# YTM32Z1LS0 register map
Vendor: YTMicro; File version: 1.2
CPU: CM0PLUS r0p1, little endian, MPU, FPU, 2 interrupt priority bits
Registers are 32-bit, read-write, reset 0x0 unless marked. A register's access mark holds for its fields unless they carry their own. Offsets are from the block's base; [hi:lo] are bit positions; {n}, {i} and the like mark numbered series.

## pTMR0 — Periodic timer
Base 0x40037000; register names take the prefix pTMR0_
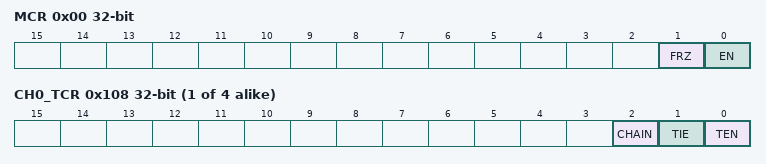
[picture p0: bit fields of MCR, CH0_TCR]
0x00 MCR
  [1] FRZ — Allows the timers to be stopped when the device enters debug mode.
    0=pTMR continues to run in debug mode; 1=pTMR stops in debug mode
  [0] EN — Enable pTMR module
    0=pTMR is disabled; 1=pTMR is enabled
{0x100+0x10*i} CH{i}_TSV (i=0..3) — Timer Start Value Register
  [31:0] STVAL — This register set the timer start value. The timer will count down until it reaches 0, then it will generate an interrupt and loads the value again. Writing a new value to this register will not restart the timer, instead the value will be loaded once the timer expires. To abort the current cycle and start a timer period with the new value, the timer must be disabled and enabled again.
{0x104+0x10*i} CH{i}_TCV (i=0..3) — Timer Current Value Register
  [31:0] CVAL — This register stands for current timer value when user read this register. The value of this register will be frozen in debug mode if MCR[FRZ] is set.
{0x108+0x10*i} CH{i}_TCR (i=0..3) — Timer Control Register
  [2] CHAIN — When setting this bit, it will link multi-channel in sequence to combine a new bits counter, it just links the front channel.
    0=Chaining is disabled, channel timer runs independently; 1=Chaining is enabled
  [1] TIE — Enable interrupt when setting this bit
    0=Disable timer interrupt of corresponding channel; 1=Enable timer interrupt of corresponding channel
  [0] TEN — Enable the timer of corresponding channel
    0=Disable the timer of corresponding channel; 1=Enable the timer of corresponding channel
{0x10C+0x10*i} CH{i}_TFR (i=0..3) — Timer Flag Register
  [0] TIF — Hardware will set this bit as 1 when timer interrupt is enabled, and writing logic 1 to this bit will clear this bit as 0.
    0=Timeout did not occur; 1=Timeout occurred

## CRC — Cyclic Redundancy Check
Base 0x40032000; register names take the prefix CRC_
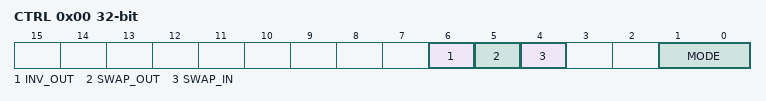
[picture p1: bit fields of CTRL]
0x00 CTRL
  [6] INV_OUT — Bit-invertion for all CRC output bits.
    0=Disable the bit-inversion; 1=Enable the bit-inversion
  [5] SWAP_OUT — Swap all the valid bits (4/16/32-bit) for CRC output data.
    0=Disable the output bit-swap; 1=Enable the output bit-swap
  [4] SWAP_IN — Enable bit-swap in each byte for CRC input data.
    0=Disable the input bit-swap; 1=Enable the input bit-swap
  [1:0] MODE — Select CRC calculation mode.
    0=Select CRC-4 mode; 1=Select CRC-16 mode; 2=Select CRC-32 mode
0x04 INIT
  [31:0] SEED — This register contains the CRC initial seed value.
0x08 IN32 wo
  [31:0] DATA rw — CRC data input in 32 bits
0x0C RESULT ro
  [31:0] RESULT rw — This register contains the result of CRC calculation. In CRC-16 mode, only the low 16 bits are valid. In CRC-4 mode, only the low 4 bits are valid.

## WDG0 — Watchdog module
Base 0x40052000; register names take the prefix WDG0_
0x00 SVCR — Watchdog Service Code Register
  [15:0] SVCODE wo — It can be used to service the watchdog or to clear the soft lock bit. Writing 0xB631 followed by 0xC278 will clear the soft lock bit, writing 0xA518 followed by 0xD826 to service the watchdog.
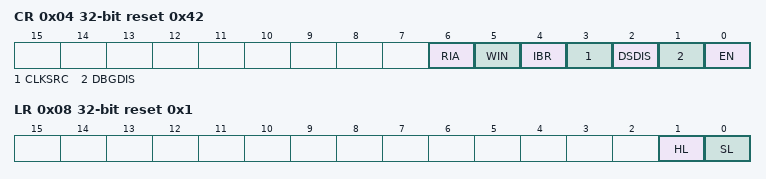
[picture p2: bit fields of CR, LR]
0x04 CR reset 0x42 — Watchdog Control Register
  [6] RIA — Enable reset for invalid APB access.
    0=Disable to generate reset by invalid APB access; 1=Enable to generate reset by invalid APB access
  [5] WIN — Enable window mode.
    0=Disable window mode, watchdog service can be done at any time; 1=Enable window mode, watchdog service is can only be done when timer value is less than the value of WIN register
  [4] IBR — Enable interrupt before reset function
    0=Disable interrupt before reset; 1=Enable interrupt before reset, when watchdog time-out, generate an interrupt first and when next time-out happens, generate reset
  [3] CLKSRC
    0=Clock from SXOSC; 1=Clock from SIRC
  [2] DSDIS — Enable or disable watchdog in deepsleep mode
    0=Enable watchdog in deepsleep mode; 1=Disable watchdog in deepsleep mode
  [1] DBGDIS — Enable or disable watchdog in debug mode.
    0=Enable watchdog in debug mode; 1=Disable watchdog in debug mode
  [0] EN — Enable watchdog module.
    0=Disable watchdog module; 1=Enable watchdog module
0x08 LR reset 0x1 — Watchdog Lock Register
  [1] HL — Hard lock, when this bit set, the CR, WIN, TO are read-only. once set, the bit can only be clear by reset.
  [0] SL — Soft lock, when this bit set, the CR, WIN, TO are read-only. this bit can be clear by writing a valid sequence to SVR register.
0x0C TOVR reset 0x300 — Watchdog Timer Overflow Value
  [31:0] TO — A 32bit down counter uses this value to start count down. ote{This register can be configured to any value, it is crucial to verify the alignment between the actual WDG reset time and the TOVR[TO] register value prior to its configuration. ewline ewline For instance, when WDG clock source is chosen from a clock with the period of 500ns, and this register bit is set to a relatively low value such as 0x10, the WDG reset interval will be adjust to 16*0.5us = 8us upon enabling WDG. This implies that WDG must be serviced every 8us to prevent a WDG reset. Obviously if the core is excuting a complex application, this service interval may be impractically short. The method for calculating WDG reset time remains consistent when alternative clock sources are selected. ewline ewline extbf{In general, it is advisable to avoid configuring this register with a value less than 0x100!} }
0x10 WVR
  [31:0] WIN — When CR[WIN] is set, the window mode is enabled, the service sequence can only be written when the timer value is less than the value of this register.
0x14 CNTCVR — Watchdog Counter Current Value Register
  [31:0] CVAL ro — Watchdog counter current value.
0x18 INTF — Watchdog Interrupt Flag register
  [0] IF — Watchdog interrupt flag. Write 1 to this field to clear the flag and interrupt.
    0=No watchdog interrupt is pending; 1=Watchdog timer time-out interrupt is pending

## EMU0 — ECC Management Unit (EMU)
Base 0x40018000; register names take the prefix EMU0_
0x00 EIGCR
  [0] GEN — This bit will enable or disable all error injection functions.
    0=Global error injection is disabled; 1=Global error injection is enabled
0x04 EICHCR
  [0] CH0EN — This field enable channel 0 error injection function. Enable channel 0 error injection function should enable this field and EIGCR[GEN]. Any write to EICHD0_ADDR, EICHD0_CHKBIT, EICHD0_DATA0 register will clear this field.
    0=Channel 0 error injection is disabled; 1=Channel 0 error injection is enabled
0x10 EICHD0_ADDR
  [31:0] ADDR — This field defines which addr will be injected error when read access. when the ADDR is not 0, error will be injected according to this field's value. if ADDR is 0, Error will be injected at all read access.
0x14 EICHD0_CHKBIT
  [6:0] CHKBIT — This field defines a bit-mapped mask that specifies whether the corresponding bit of the checkbit bus from the target SRAM should be inverted or remain unmodified.
    0=The corresponding bit of the checkbit bus remains unmodified; 1=The corresponding bit of the checkbit bus is inverted
0x18 EICHD0_DATA
  [31:0] DATA — This field defines a bit-mapped mask that specifies whether the corresponding bit of the read data bus from the target SRAM should be inverted or remain unmodified. 0b - The corresponding bit of the checkbit bus remains unmodified. 1b - The corresponding bit of the checkbit bus is inverted.
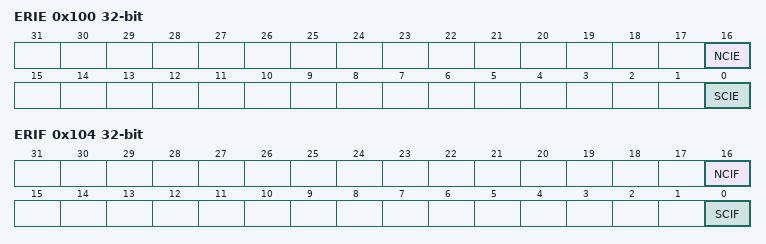
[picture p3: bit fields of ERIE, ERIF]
0x100 ERIE
  [16] NCIE — SRAM Non-Correctable error interrupt enable.
    0=SRAM Non-Correctable Error interrupt is disabled; 1=SRAM Non-Correctable Error interrupt is enabled
  [0] SCIE — SRAM Single correctable error interrupt enable.
    0=SRAM Single Correctable Error interrupt is disabled; 1=SRAM Single Correctable Error interrupt is enabled
0x104 ERIF
  [16] NCIF — SRAM Non-Correctable error interrupt flag.
    0=SRAM Non-Correctable Error interrupt not detected; 1=SRAM Non-Correctable Error interrupt detected
  [0] SCIF — SRAM Single Correctable error interrupt flag.
    0=SRAM Single Correctable Error interrupt not detected; 1=SRAM Single Correctable Error interrupt detected
0x110 ERINFO0_ADDR ro
  [31:0] ADDR — This field contains the faulting system address of the last recorded ECC event on SRAM.
0x114 ERINFO0_SYND ro
  [6:0] SYNDROME — This field contains the syndrome of the last recorded ECC event on SRAM.
0x118 ERINFO0_CNT wo
  [7:0] CNT rw — For each correctable error event, the EMU increments this field's error count value until the counter reaches its maximum value 0xFF. CNT will not change once it reaches 0xFF and will not wrap even if error occurs. Read this field to determine the correctable error count value so far. Write zero to this field to reset the counter. Writing non-zero (or partial zero) values has no effect.
